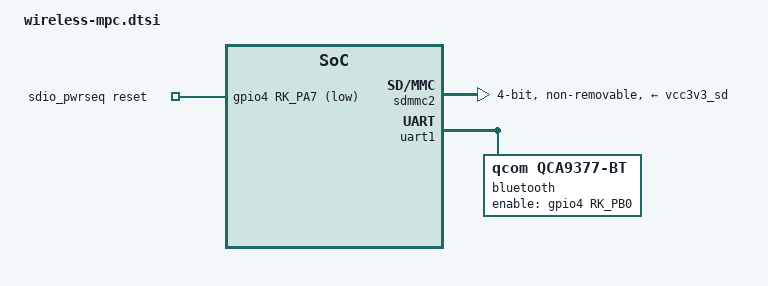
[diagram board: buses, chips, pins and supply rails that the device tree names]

/ {

	sdio_pwrseq: sdio-pwrseq {
		compatible = "mmc-pwrseq-simple";
	
    pinctrl-names = "default";
		pinctrl-0 = <&wlan_en_pin>;
		post-power-on-delay-ms = <200>;
		// WLAN_EN
		reset-gpios = <&gpio4 RK_PA7 GPIO_ACTIVE_LOW>;
	};

  wireless_wlan: wireless-wlan {
    compatible = "wlan-platdata";
    rockchip,grf = <&grf>;
 		clocks = <&hym8563>;
		clock-names = "ext_clock";
    wifi_chip_type = "mywifi";
    status = "okay";
  };

};

&sdmmc2 {
  // WiFi & BT combo module Fn-Link FG6233ASRB-01 / Fn-Link 8223A-SR
  mmc-pwrseq = <&sdio_pwrseq>;
  pinctrl-names = "default";
  pinctrl-0 = <&sdmmc2m0_bus4 &sdmmc2m0_clk &sdmmc2m0_cmd>;
  vmmc-supply = <&vcc3v3_sd>;
  vqmmc-supply = <&vcc3v3_sd>;

  bus-width = <4>;
  max-frequency = <10000000>;
//  drv-type = <2>;
  cap-sd-highspeed;
//  sd-uhs-sdr50;
//  sd-uhs-sdr104;
  keep-power-in-suspend;
  enable-sdio-wakeup;
  cap-sdio-irq;
  non-removable;
  no-mmc;
  no-sd;

  #address-cells = <1>;
  #size-cells = <0>;
  rockchip,default-sample-phase = <90>;
  status = "okay";

//  qca_wifi: qca-wifi@1 {
//    reg = <1>;
//    compatible = "qcom,ath10k";
//  };
};

&uart1 {
  pinctrl-names = "default";
  pinctrl-0 = <&uart1m1_xfer &uart1m1_ctsn &uart1m1_rtsn>;
  uart-has-rtscts;
  status = "okay";

  bluetooth {
//    TODO
    // Fn-Link FG6233ASRB-01
//    compatible = "realtek,rtl8723bs-bt";
    // Fn-Link 8223A-SR
    compatible = "qcom,qca9377-bt";
    // BT_WAKE_HOST
//    device-wake-gpios = <&gpio3 RK_PA1 GPIO_ACTIVE_HIGH>;
    // WL_HOST_WAKE
//    host-wake-gpios = <&gpio3 RK_PD4 GPIO_ACTIVE_HIGH>;
    // BT_EN
    enable-gpios = <&gpio4 RK_PB0 GPIO_ACTIVE_HIGH>;
    max-speed = <2000000>;
    pinctrl-names = "default";
    pinctrl-0 = <&bt_en_pin>;
  };
};


&pinctrl {
	sdio-pwrseq {
/*
		WLAN_EN is pulled down to GND via R237(10K)
*/
		wlan_en_pin: wlan-en-pin {
			rockchip,pins = <4 RK_PA7 RK_FUNC_GPIO &pcfg_pull_none>;
		};
	};
/*
	This signal is absent on the board

	wireless-wlan {
		wifi_host_wake_irq: wifi-host-wake-irq {
			rockchip,pins = <3 RK_PD4 RK_FUNC_GPIO &pcfg_pull_down>;
		};
	};
*/
	wireless-bluetooth {
		// UART1_RTS
		uart1_gpios: uart1-gpios {
			rockchip,pins = <4 RK_PB6 RK_FUNC_GPIO &pcfg_pull_none>;
		};
/*
		BT_EN is pulled down to GND via R238(10K)
*/        
        bt_en_pin: bt-en-pin {
			rockchip,pins = <4 RK_PB0 RK_FUNC_GPIO &pcfg_pull_none>;
		};
	};
};
